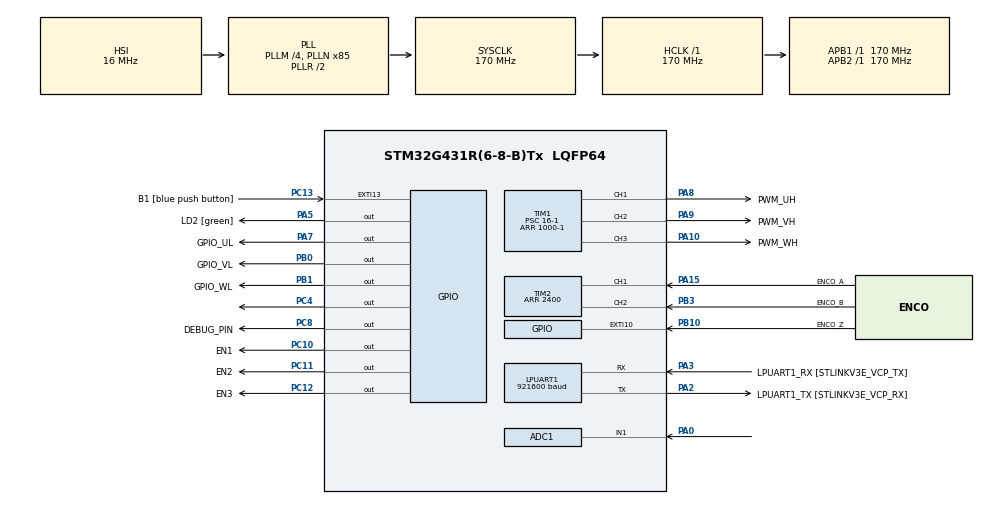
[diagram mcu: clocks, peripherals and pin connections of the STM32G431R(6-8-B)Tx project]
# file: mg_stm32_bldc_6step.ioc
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ADC1.Channel-2\#ChannelRegularConversion=ADC_CHANNEL_1
ADC1.ExternalTrigConv=ADC_EXTERNALTRIG_T1_TRGO
ADC1.NbrOfConversionFlag=1
ADC1.OffsetNumber-2\#ChannelRegularConversion=ADC_OFFSET_NONE
ADC1.Rank-2\#ChannelRegularConversion=1
ADC1.SamplingTime-2\#ChannelRegularConversion=ADC_SAMPLETIME_47CYCLES_5
ADC1.master=1
LPUART1.BaudRate=921600
Mcu.Family=STM32G4
Mcu.Name=STM32G431R(6-8-B)Tx
Mcu.Package=LQFP64
NVIC.ADC1_2_IRQn=true\:0\:0\:false\:false\:true\:true\:true\:true
NVIC.EXTI15_10_IRQn=true\:0\:0\:false\:false\:true\:true\:true\:true
NVIC.LPUART1_IRQn=true\:0\:0\:false\:false\:true\:true\:true\:true
NVIC.PriorityGroup=NVIC_PRIORITYGROUP_4
NVIC.TIM2_IRQn=true\:0\:0\:false\:false\:true\:true\:true\:true
NVIC.TIM3_IRQn=true\:0\:0\:false\:false\:true\:true\:true\:true
PA0.Mode=IN1-Single-Ended
PA0.Signal=ADC1_IN1
PA10.GPIO_Label=PWM_WH
PA10.Signal=S_TIM1_CH3
PA13.GPIO_Label=T_SWDIO
PA13.Signal=SYS_JTMS-SWDIO
PA14.GPIO_Label=T_SWCLK
PA14.Signal=SYS_JTCK-SWCLK
PA15.GPIO_Label=ENCO_A
PA15.Signal=S_TIM2_CH1
PA2.GPIO_Label=LPUART1_TX [STLINKV3E_VCP_RX]
PA2.Mode=Asynchronous
PA2.Signal=LPUART1_TX
PA3.GPIO_Label=LPUART1_RX [STLINKV3E_VCP_TX]
PA3.Mode=Asynchronous
PA3.Signal=LPUART1_RX
PA5.GPIO_Label=LD2 [green]
PA5.Signal=GPIO_Output
PA7.GPIO_Label=GPIO_UL
PA7.Signal=GPIO_Output
PA8.GPIO_Label=PWM_UH
PA8.Signal=S_TIM1_CH1
PA9.GPIO_Label=PWM_VH
PA9.Signal=S_TIM1_CH2
PB0.GPIO_Label=GPIO_VL
PB0.Signal=GPIO_Output
PB1.GPIO_Label=GPIO_WL
PB1.Signal=GPIO_Output
PB10.GPIO_Label=ENCO_Z
PB10.Signal=GPXTI10
PB3.GPIO_Label=ENCO_B
PB3.Signal=S_TIM2_CH2
PC10.GPIO_Label=EN1
PC10.PinState=GPIO_PIN_RESET
PC10.Signal=GPIO_Output
PC11.GPIO_Label=EN2
PC11.PinState=GPIO_PIN_RESET
PC11.Signal=GPIO_Output
PC12.GPIO_Label=EN3
PC12.PinState=GPIO_PIN_RESET
PC12.Signal=GPIO_Output
PC13.GPIO_Label=B1 [blue push button]
PC13.Signal=GPXTI13
PC4.Signal=GPIO_Output
PC8.GPIO_Label=DEBUG_PIN
PC8.Signal=GPIO_Output
ProjectManager.HeapSize=0x200
ProjectManager.StackSize=0x400
ProjectManager.TargetToolchain=STM32CubeIDE
RCC.ADC12Freq_Value=170000000
RCC.AHBFreq_Value=170000000
RCC.APB1Freq_Value=170000000
RCC.APB1TimFreq_Value=170000000
RCC.APB2Freq_Value=170000000
RCC.APB2TimFreq_Value=170000000
RCC.CortexFreq_Value=170000000
RCC.EXTERNAL_CLOCK_VALUE=12288000
RCC.HCLKFreq_Value=170000000
RCC.HSE_VALUE=24000000
RCC.HSI48_VALUE=48000000
RCC.HSI_VALUE=16000000
RCC.LSE_VALUE=32768
RCC.PLLM=RCC_PLLM_DIV4
RCC.PLLN=85
RCC.RTCClockSelection=RCC_RTCCLKSOURCE_LSE
RCC.SYSCLKFreq_VALUE=170000000
RCC.SYSCLKSource=RCC_SYSCLKSOURCE_PLLCLK
RCC.USBFreq_Value=170000000
RCC.VCOOutputFreq_Value=340000000
SH.S_TIM1_CH1.0=TIM1_CH1,PWM Generation1 CH1
SH.S_TIM1_CH2.0=TIM1_CH2,PWM Generation2 CH2
SH.S_TIM1_CH3.0=TIM1_CH3,PWM Generation3 CH3
SH.S_TIM2_CH1.0=TIM2_CH1,Encoder_Interface
SH.S_TIM2_CH2.0=TIM2_CH2,Encoder_Interface
TIM1.Channel-PWM\ Generation1\ CH1=TIM_CHANNEL_1
TIM1.Channel-PWM\ Generation2\ CH2=TIM_CHANNEL_2
TIM1.Channel-PWM\ Generation3\ CH3=TIM_CHANNEL_3
TIM1.CounterMode=TIM_COUNTERMODE_CENTERALIGNED1
TIM1.PeriodNoDither=1000-1
TIM1.Prescaler=16-1
TIM1.TIM_MasterOutputTrigger=TIM_TRGO_OC2REF
TIM2.EncoderMode=TIM_ENCODERMODE_TI12
TIM2.IC1Filter=0
TIM2.IC2Filter=0
TIM2.PeriodNoDither=2400
TIM3.PeriodNoDither=170-1
TIM3.Prescaler=10
VP_SYS_VS_DBSignals.Mode=DisableDeadBatterySignals
VP_TIM1_VS_ClockSourceINT.Mode=Internal
VP_TIM3_VS_ClockSourceINT.Mode=Internal
board=NUCLEO-G431RB

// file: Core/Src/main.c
/* USER CODE BEGIN Header */
/**
  ******************************************************************************
  * @file           : main.c
  * @brief          : Main program body
  ******************************************************************************
  * @attention
  *
  * Copyright (c) 2025 STMicroelectronics.
  * All rights reserved.
  *
  * This software is licensed under terms that can be found in the LICENSE file
  * in the root directory of this software component.
  * If no LICENSE file comes with this software, it is provided AS-IS.
  *
  ******************************************************************************
  */
/* USER CODE END Header */
#include "main.h"

/* USER CODE BEGIN Includes */
#include "app_1.h"
/* USER CODE END Includes */

ADC_HandleTypeDef hadc1;

UART_HandleTypeDef hlpuart1;

TIM_HandleTypeDef htim1;
TIM_HandleTypeDef htim2;
TIM_HandleTypeDef htim3;

void SystemClock_Config(void);
static void MX_GPIO_Init(void);
static void MX_LPUART1_UART_Init(void);
static void MX_TIM1_Init(void);
static void MX_TIM2_Init(void);
static void MX_TIM3_Init(void);
static void MX_ADC1_Init(void);

int main(void)
{

  /* MCU Configuration--------------------------------------------------------*/

  /* Reset of all peripherals, Initializes the Flash interface and the Systick. */
  HAL_Init();

  /* Configure the system clock */
  SystemClock_Config();

  /* Initialize all configured peripherals */
  MX_GPIO_Init();
  MX_LPUART1_UART_Init();
  MX_TIM1_Init();
  MX_TIM2_Init();
  MX_TIM3_Init();
  MX_ADC1_Init();
  /* USER CODE BEGIN 2 */
  init_app1();
  /* USER CODE END 2 */

  /* Infinite loop */
  while (1)
  {

  }
}

void SystemClock_Config(void)
{
  RCC_OscInitTypeDef RCC_OscInitStruct = {0};
  RCC_ClkInitTypeDef RCC_ClkInitStruct = {0};

  /** Configure the main internal regulator output voltage
  */
  HAL_PWREx_ControlVoltageScaling(PWR_REGULATOR_VOLTAGE_SCALE1_BOOST);

  /** Initializes the RCC Oscillators according to the specified parameters
  * in the RCC_OscInitTypeDef structure.
  */
  RCC_OscInitStruct.OscillatorType = RCC_OSCILLATORTYPE_HSI;
  RCC_OscInitStruct.HSIState = RCC_HSI_ON;
  RCC_OscInitStruct.HSICalibrationValue = RCC_HSICALIBRATION_DEFAULT;
  RCC_OscInitStruct.PLL.PLLState = RCC_PLL_ON;
  RCC_OscInitStruct.PLL.PLLSource = RCC_PLLSOURCE_HSI;
  RCC_OscInitStruct.PLL.PLLM = RCC_PLLM_DIV4;
  RCC_OscInitStruct.PLL.PLLN = 85;
  RCC_OscInitStruct.PLL.PLLP = RCC_PLLP_DIV2;
  RCC_OscInitStruct.PLL.PLLQ = RCC_PLLQ_DIV2;
  RCC_OscInitStruct.PLL.PLLR = RCC_PLLR_DIV2;
  if (HAL_RCC_OscConfig(&RCC_OscInitStruct) != HAL_OK)
  {
    Error_Handler();
  }

  /** Initializes the CPU, AHB and APB buses clocks
  */
  RCC_ClkInitStruct.ClockType = RCC_CLOCKTYPE_HCLK|RCC_CLOCKTYPE_SYSCLK
                              |RCC_CLOCKTYPE_PCLK1|RCC_CLOCKTYPE_PCLK2;
  RCC_ClkInitStruct.SYSCLKSource = RCC_SYSCLKSOURCE_PLLCLK;
  RCC_ClkInitStruct.AHBCLKDivider = RCC_SYSCLK_DIV1;
  RCC_ClkInitStruct.APB1CLKDivider = RCC_HCLK_DIV1;
  RCC_ClkInitStruct.APB2CLKDivider = RCC_HCLK_DIV1;

  if (HAL_RCC_ClockConfig(&RCC_ClkInitStruct, FLASH_LATENCY_4) != HAL_OK)
  {
    Error_Handler();
  }
}

static void MX_ADC1_Init(void)
{

  ADC_MultiModeTypeDef multimode = {0};
  ADC_ChannelConfTypeDef sConfig = {0};

  /** Common config
  */
  hadc1.Instance = ADC1;
  hadc1.Init.ClockPrescaler = ADC_CLOCK_SYNC_PCLK_DIV4;
  hadc1.Init.Resolution = ADC_RESOLUTION_12B;
  hadc1.Init.DataAlign = ADC_DATAALIGN_RIGHT;
  hadc1.Init.GainCompensation = 0;
  hadc1.Init.ScanConvMode = ADC_SCAN_DISABLE;
  hadc1.Init.EOCSelection = ADC_EOC_SINGLE_CONV;
  hadc1.Init.LowPowerAutoWait = DISABLE;
  hadc1.Init.ContinuousConvMode = DISABLE;
  hadc1.Init.NbrOfConversion = 1;
  hadc1.Init.DiscontinuousConvMode = DISABLE;
  hadc1.Init.ExternalTrigConv = ADC_EXTERNALTRIG_T1_TRGO;
  hadc1.Init.ExternalTrigConvEdge = ADC_EXTERNALTRIGCONVEDGE_RISING;
  hadc1.Init.DMAContinuousRequests = DISABLE;
  hadc1.Init.Overrun = ADC_OVR_DATA_PRESERVED;
  hadc1.Init.OversamplingMode = DISABLE;
  if (HAL_ADC_Init(&hadc1) != HAL_OK)
  {
    Error_Handler();
  }

  /** Configure the ADC multi-mode
  */
  multimode.Mode = ADC_MODE_INDEPENDENT;
  if (HAL_ADCEx_MultiModeConfigChannel(&hadc1, &multimode) != HAL_OK)
  {
    Error_Handler();
  }

  /** Configure Regular Channel
  */
  sConfig.Channel = ADC_CHANNEL_1;
  sConfig.Rank = ADC_REGULAR_RANK_1;
  sConfig.SamplingTime = ADC_SAMPLETIME_47CYCLES_5;
  sConfig.SingleDiff = ADC_SINGLE_ENDED;
  sConfig.OffsetNumber = ADC_OFFSET_NONE;
  sConfig.Offset = 0;
  if (HAL_ADC_ConfigChannel(&hadc1, &sConfig) != HAL_OK)
  {
    Error_Handler();
  }

}

static void MX_LPUART1_UART_Init(void)
{

  hlpuart1.Instance = LPUART1;
  hlpuart1.Init.BaudRate = 921600;
  hlpuart1.Init.WordLength = UART_WORDLENGTH_8B;
  hlpuart1.Init.StopBits = UART_STOPBITS_1;
  hlpuart1.Init.Parity = UART_PARITY_NONE;
  hlpuart1.Init.Mode = UART_MODE_TX_RX;
  hlpuart1.Init.HwFlowCtl = UART_HWCONTROL_NONE;
  hlpuart1.Init.OneBitSampling = UART_ONE_BIT_SAMPLE_DISABLE;
  hlpuart1.Init.ClockPrescaler = UART_PRESCALER_DIV1;
  hlpuart1.AdvancedInit.AdvFeatureInit = UART_ADVFEATURE_NO_INIT;
  if (HAL_UART_Init(&hlpuart1) != HAL_OK)
  {
    Error_Handler();
  }
  if (HAL_UARTEx_SetTxFifoThreshold(&hlpuart1, UART_TXFIFO_THRESHOLD_1_8) != HAL_OK)
  {
    Error_Handler();
  }
  if (HAL_UARTEx_SetRxFifoThreshold(&hlpuart1, UART_RXFIFO_THRESHOLD_1_8) != HAL_OK)
  {
    Error_Handler();
  }
  if (HAL_UARTEx_DisableFifoMode(&hlpuart1) != HAL_OK)
  {
    Error_Handler();
  }

}

static void MX_TIM1_Init(void)
{

  TIM_ClockConfigTypeDef sClockSourceConfig = {0};
  TIM_MasterConfigTypeDef sMasterConfig = {0};
  TIM_OC_InitTypeDef sConfigOC = {0};
  TIM_BreakDeadTimeConfigTypeDef sBreakDeadTimeConfig = {0};

  htim1.Instance = TIM1;
  htim1.Init.Prescaler = 16-1;
  htim1.Init.CounterMode = TIM_COUNTERMODE_CENTERALIGNED1;
  htim1.Init.Period = 999;
  htim1.Init.ClockDivision = TIM_CLOCKDIVISION_DIV1;
  htim1.Init.RepetitionCounter = 0;
  htim1.Init.AutoReloadPreload = TIM_AUTORELOAD_PRELOAD_DISABLE;
  if (HAL_TIM_Base_Init(&htim1) != HAL_OK)
  {
    Error_Handler();
  }
  sClockSourceConfig.ClockSource = TIM_CLOCKSOURCE_INTERNAL;
  if (HAL_TIM_ConfigClockSource(&htim1, &sClockSourceConfig) != HAL_OK)
  {
    Error_Handler();
  }
  if (HAL_TIM_PWM_Init(&htim1) != HAL_OK)
  {
    Error_Handler();
  }
  sMasterConfig.MasterOutputTrigger = TIM_TRGO_OC2REF;
  sMasterConfig.MasterOutputTrigger2 = TIM_TRGO2_RESET;
  sMasterConfig.MasterSlaveMode = TIM_MASTERSLAVEMODE_DISABLE;
  if (HAL_TIMEx_MasterConfigSynchronization(&htim1, &sMasterConfig) != HAL_OK)
  {
    Error_Handler();
  }
  sConfigOC.OCMode = TIM_OCMODE_PWM1;
  sConfigOC.Pulse = 0;
  sConfigOC.OCPolarity = TIM_OCPOLARITY_HIGH;
  sConfigOC.OCNPolarity = TIM_OCNPOLARITY_HIGH;
  sConfigOC.OCFastMode = TIM_OCFAST_DISABLE;
  sConfigOC.OCIdleState = TIM_OCIDLESTATE_RESET;
  sConfigOC.OCNIdleState = TIM_OCNIDLESTATE_RESET;
  if (HAL_TIM_PWM_ConfigChannel(&htim1, &sConfigOC, TIM_CHANNEL_1) != HAL_OK)
  {
    Error_Handler();
  }
  if (HAL_TIM_PWM_ConfigChannel(&htim1, &sConfigOC, TIM_CHANNEL_2) != HAL_OK)
  {
    Error_Handler();
  }
  if (HAL_TIM_PWM_ConfigChannel(&htim1, &sConfigOC, TIM_CHANNEL_3) != HAL_OK)
  {
    Error_Handler();
  }
  sBreakDeadTimeConfig.OffStateRunMode = TIM_OSSR_DISABLE;
  sBreakDeadTimeConfig.OffStateIDLEMode = TIM_OSSI_DISABLE;
  sBreakDeadTimeConfig.LockLevel = TIM_LOCKLEVEL_OFF;
  sBreakDeadTimeConfig.DeadTime = 0;
  sBreakDeadTimeConfig.BreakState = TIM_BREAK_DISABLE;
  sBreakDeadTimeConfig.BreakPolarity = TIM_BREAKPOLARITY_HIGH;
  sBreakDeadTimeConfig.BreakFilter = 0;
  sBreakDeadTimeConfig.BreakAFMode = TIM_BREAK_AFMODE_INPUT;
  sBreakDeadTimeConfig.Break2State = TIM_BREAK2_DISABLE;
  sBreakDeadTimeConfig.Break2Polarity = TIM_BREAK2POLARITY_HIGH;
  sBreakDeadTimeConfig.Break2Filter = 0;
  sBreakDeadTimeConfig.Break2AFMode = TIM_BREAK_AFMODE_INPUT;
  sBreakDeadTimeConfig.AutomaticOutput = TIM_AUTOMATICOUTPUT_DISABLE;
  if (HAL_TIMEx_ConfigBreakDeadTime(&htim1, &sBreakDeadTimeConfig) != HAL_OK)
  {
    Error_Handler();
  }
  HAL_TIM_MspPostInit(&htim1);

}

static void MX_TIM2_Init(void)
{

  TIM_Encoder_InitTypeDef sConfig = {0};
  TIM_MasterConfigTypeDef sMasterConfig = {0};

  htim2.Instance = TIM2;
  htim2.Init.Prescaler = 0;
  htim2.Init.CounterMode = TIM_COUNTERMODE_UP;
  htim2.Init.Period = 2400;
  htim2.Init.ClockDivision = TIM_CLOCKDIVISION_DIV1;
  htim2.Init.AutoReloadPreload = TIM_AUTORELOAD_PRELOAD_DISABLE;
  sConfig.EncoderMode = TIM_ENCODERMODE_TI12;
  sConfig.IC1Polarity = TIM_ICPOLARITY_RISING;
  sConfig.IC1Selection = TIM_ICSELECTION_DIRECTTI;
  sConfig.IC1Prescaler = TIM_ICPSC_DIV1;
  sConfig.IC1Filter = 0;
  sConfig.IC2Polarity = TIM_ICPOLARITY_RISING;
  sConfig.IC2Selection = TIM_ICSELECTION_DIRECTTI;
  sConfig.IC2Prescaler = TIM_ICPSC_DIV1;
  sConfig.IC2Filter = 0;
  if (HAL_TIM_Encoder_Init(&htim2, &sConfig) != HAL_OK)
  {
    Error_Handler();
  }
  sMasterConfig.MasterOutputTrigger = TIM_TRGO_RESET;
  sMasterConfig.MasterSlaveMode = TIM_MASTERSLAVEMODE_DISABLE;
  if (HAL_TIMEx_MasterConfigSynchronization(&htim2, &sMasterConfig) != HAL_OK)
  {
    Error_Handler();
  }

}

static void MX_TIM3_Init(void)
{

  TIM_ClockConfigTypeDef sClockSourceConfig = {0};
  TIM_MasterConfigTypeDef sMasterConfig = {0};

  htim3.Instance = TIM3;
  htim3.Init.Prescaler = 10;
  htim3.Init.CounterMode = TIM_COUNTERMODE_UP;
  htim3.Init.Period = 169;
  htim3.Init.ClockDivision = TIM_CLOCKDIVISION_DIV1;
  htim3.Init.AutoReloadPreload = TIM_AUTORELOAD_PRELOAD_DISABLE;
  if (HAL_TIM_Base_Init(&htim3) != HAL_OK)
  {
    Error_Handler();
  }
  sClockSourceConfig.ClockSource = TIM_CLOCKSOURCE_INTERNAL;
  if (HAL_TIM_ConfigClockSource(&htim3, &sClockSourceConfig) != HAL_OK)
  {
    Error_Handler();
  }
  sMasterConfig.MasterOutputTrigger = TIM_TRGO_RESET;
  sMasterConfig.MasterSlaveMode = TIM_MASTERSLAVEMODE_DISABLE;
  if (HAL_TIMEx_MasterConfigSynchronization(&htim3, &sMasterConfig) != HAL_OK)
  {
    Error_Handler();
  }

}

static void MX_GPIO_Init(void)
{
  GPIO_InitTypeDef GPIO_InitStruct = {0};

  /* GPIO Ports Clock Enable */
  __HAL_RCC_GPIOC_CLK_ENABLE();
  __HAL_RCC_GPIOA_CLK_ENABLE();
  __HAL_RCC_GPIOB_CLK_ENABLE();

  /*Configure GPIO pin Output Level */
  HAL_GPIO_WritePin(GPIOA, LD2_Pin|GPIO_UL_Pin, GPIO_PIN_RESET);

  /*Configure GPIO pin Output Level */
  HAL_GPIO_WritePin(GPIOC, GPIO_PIN_4|DEBUG_PIN_Pin|EN1_Pin|EN2_Pin
                          |EN3_Pin, GPIO_PIN_RESET);

  /*Configure GPIO pin Output Level */
  HAL_GPIO_WritePin(GPIOB, GPIO_VL_Pin|GPIO_WL_Pin, GPIO_PIN_RESET);

  /*Configure GPIO pin : B1_Pin */
  GPIO_InitStruct.Pin = B1_Pin;
  GPIO_InitStruct.Mode = GPIO_MODE_IT_RISING;
  GPIO_InitStruct.Pull = GPIO_NOPULL;
  HAL_GPIO_Init(B1_GPIO_Port, &GPIO_InitStruct);

  /*Configure GPIO pins : LD2_Pin GPIO_UL_Pin */
  GPIO_InitStruct.Pin = LD2_Pin|GPIO_UL_Pin;
  GPIO_InitStruct.Mode = GPIO_MODE_OUTPUT_PP;
  GPIO_InitStruct.Pull = GPIO_NOPULL;
  GPIO_InitStruct.Speed = GPIO_SPEED_FREQ_LOW;
  HAL_GPIO_Init(GPIOA, &GPIO_InitStruct);

  /*Configure GPIO pins : PC4 DEBUG_PIN_Pin EN1_Pin EN2_Pin
                           EN3_Pin */
  GPIO_InitStruct.Pin = GPIO_PIN_4|DEBUG_PIN_Pin|EN1_Pin|EN2_Pin
                          |EN3_Pin;
  GPIO_InitStruct.Mode = GPIO_MODE_OUTPUT_PP;
  GPIO_InitStruct.Pull = GPIO_NOPULL;
  GPIO_InitStruct.Speed = GPIO_SPEED_FREQ_LOW;
  HAL_GPIO_Init(GPIOC, &GPIO_InitStruct);

  /*Configure GPIO pins : GPIO_VL_Pin GPIO_WL_Pin */
  GPIO_InitStruct.Pin = GPIO_VL_Pin|GPIO_WL_Pin;
  GPIO_InitStruct.Mode = GPIO_MODE_OUTPUT_PP;
  GPIO_InitStruct.Pull = GPIO_NOPULL;
  GPIO_InitStruct.Speed = GPIO_SPEED_FREQ_LOW;
  HAL_GPIO_Init(GPIOB, &GPIO_InitStruct);

  /*Configure GPIO pin : ENCO_Z_Pin */
  GPIO_InitStruct.Pin = ENCO_Z_Pin;
  GPIO_InitStruct.Mode = GPIO_MODE_IT_RISING;
  GPIO_InitStruct.Pull = GPIO_NOPULL;
  HAL_GPIO_Init(ENCO_Z_GPIO_Port, &GPIO_InitStruct);

  /* EXTI interrupt init*/
  HAL_NVIC_SetPriority(EXTI15_10_IRQn, 0, 0);
  HAL_NVIC_EnableIRQ(EXTI15_10_IRQn);

}

void Error_Handler(void)
{
  __disable_irq();
  while (1)
  {
  }
}
